VERSION "0.1.0"

NS_ :

BS_:

BU_: HPC BODY_ECU TESTER

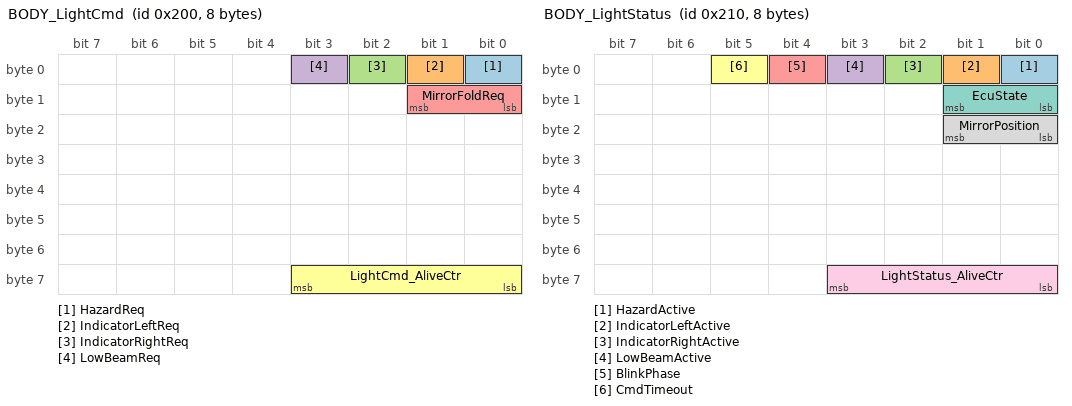
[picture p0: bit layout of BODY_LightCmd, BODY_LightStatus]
BO_ 512 BODY_LightCmd: 8 HPC
 SG_ HazardReq : 0|1@1+ (1,0) [0|1] "" BODY_ECU
 SG_ IndicatorLeftReq : 1|1@1+ (1,0) [0|1] "" BODY_ECU
 SG_ IndicatorRightReq : 2|1@1+ (1,0) [0|1] "" BODY_ECU
 SG_ LowBeamReq : 3|1@1+ (1,0) [0|1] "" BODY_ECU
 SG_ MirrorFoldReq : 8|2@1+ (1,0) [0|3] "" BODY_ECU
 SG_ LightCmd_AliveCtr : 56|4@1+ (1,0) [0|15] "" BODY_ECU

BO_ 528 BODY_LightStatus: 8 BODY_ECU
 SG_ HazardActive : 0|1@1+ (1,0) [0|1] "" HPC,TESTER
 SG_ IndicatorLeftActive : 1|1@1+ (1,0) [0|1] "" HPC,TESTER
 SG_ IndicatorRightActive : 2|1@1+ (1,0) [0|1] "" HPC,TESTER
 SG_ LowBeamActive : 3|1@1+ (1,0) [0|1] "" HPC,TESTER
 SG_ BlinkPhase : 4|1@1+ (1,0) [0|1] "" HPC,TESTER
 SG_ CmdTimeout : 5|1@1+ (1,0) [0|1] "" HPC,TESTER
 SG_ EcuState : 8|2@1+ (1,0) [0|3] "" HPC,TESTER
 SG_ MirrorPosition : 16|2@1+ (1,0) [0|3] "" HPC,TESTER
 SG_ LightStatus_AliveCtr : 56|4@1+ (1,0) [0|15] "" HPC,TESTER

CM_ "open-sdv-bench body zone CAN contract. Changes only via ADR. Bitrate 500 kbit/s, CAN classic, 11-bit IDs.";
CM_ BU_ HPC "Central vehicle computer (Raspberry Pi 5). In loopback builds the body ECU test stimulus plays this role.";
CM_ BU_ BODY_ECU "Body zone ECU (STM32F407G-DISC1): lights now, mirror servo later.";
CM_ BU_ TESTER "Diagnostic tester / observer, receive only.";
CM_ BO_ 512 "Light and mirror requests to the body ECU. Cyclic 100 ms. Missing for 500 ms = command timeout.";
CM_ BO_ 528 "Body ECU actual light and mirror state. Cyclic 100 ms.";
CM_ SG_ 512 HazardReq "1 = hazard lights requested. Overrides indicator requests.";
CM_ SG_ 512 IndicatorLeftReq "1 = left indicator requested.";
CM_ SG_ 512 IndicatorRightReq "1 = right indicator requested.";
CM_ SG_ 512 LowBeamReq "1 = low beam requested.";
CM_ SG_ 512 MirrorFoldReq "Mirror fold request. Reserved for the servo milestone; ignored in v0.1.";
CM_ SG_ 512 LightCmd_AliveCtr "Rolling counter 0..15, incremented by 1 per frame.";
CM_ SG_ 528 BlinkPhase "1 = indicator lamps currently lit (on-phase of the blink cycle).";
CM_ SG_ 528 CmdTimeout "1 = BODY_LightCmd not received for >= 500 ms; fail-safe active.";
CM_ SG_ 528 EcuState "Body ECU operating state.";
CM_ SG_ 528 MirrorPosition "Actual mirror position. Always Unknown (0) until the servo milestone.";
CM_ SG_ 528 LightStatus_AliveCtr "Rolling counter 0..15, incremented by 1 per frame.";

BA_DEF_ BO_ "GenMsgCycleTime" INT 0 65535;
BA_DEF_ BO_ "GenMsgSendType" ENUM "Cyclic","Event","CyclicIfActive";
BA_DEF_ "BusType" STRING ;
BA_DEF_ "Baudrate" INT 0 1000000;
BA_DEF_DEF_ "GenMsgCycleTime" 0;
BA_DEF_DEF_ "GenMsgSendType" "Cyclic";
BA_DEF_DEF_ "BusType" "CAN";
BA_DEF_DEF_ "Baudrate" 500000;
BA_ "GenMsgCycleTime" BO_ 512 100;
BA_ "GenMsgCycleTime" BO_ 528 100;

VAL_ 512 MirrorFoldReq 0 "NoRequest" 1 "Fold" 2 "Unfold" 3 "Reserved" ;
VAL_ 528 EcuState 0 "Init" 1 "Normal" 2 "Degraded" 3 "Fault" ;
VAL_ 528 MirrorPosition 0 "Unknown" 1 "Unfolded" 2 "Folded" 3 "Moving" ;
